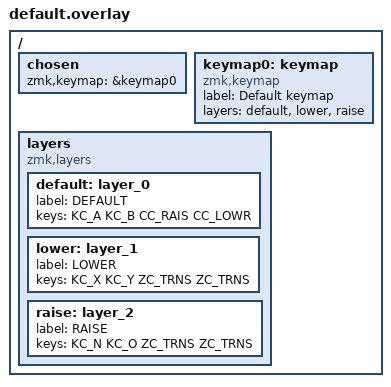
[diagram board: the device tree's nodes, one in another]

/ {
	chosen {
		zmk,keymap = &keymap0;
	};
	keymap0: keymap {
		compatible = "zmk,keymap";
		label ="Default keymap";
		layers = <&default &lower &raise>;
	};

	layers {
		compatible = "zmk,layers";

		default: layer_0 {
			label = "DEFAULT";
			keys =
	<
	KC_A    KC_B
	CC_RAIS CC_LOWR
	>;
		};

		lower: layer_1 {
			label = "LOWER";
			keys = <
			KC_X    KC_Y
			ZC_TRNS ZC_TRNS
			>;
		};

		raise: layer_2 {
			label = "RAISE";
			keys = <
			KC_N    KC_O
			ZC_TRNS ZC_TRNS
			>;
		};
	};
};

